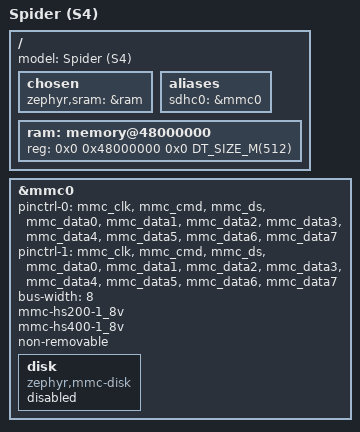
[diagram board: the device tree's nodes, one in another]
/*
 * Copyright (c) 2023 EPAM Systems
 *
 * SPDX-License-Identifier: Apache-2.0
 *
 */

/dts-v1/;
#include <mem.h>
#include <arm64/renesas/r8a779f.dtsi>
#include "spider-pinctrl.dtsi"

/ {
	model = "Spider (S4)";
	chosen {
		zephyr,sram = &ram;
	};

	/* These aliases are provided for compatibility with samples */
	aliases {
		sdhc0 = &mmc0;
	};

	ram: memory@48000000 {
		device_type = "mmio-sram";
		reg = <0x0 0x48000000 0x0 DT_SIZE_M(512)>;
	};
};

&mmc0 {
	pinctrl-0 = <&mmc_clk &mmc_cmd &mmc_ds
		&mmc_data0 &mmc_data1 &mmc_data2 &mmc_data3
		&mmc_data4 &mmc_data5 &mmc_data6 &mmc_data7>;
	pinctrl-1 = <&mmc_clk &mmc_cmd &mmc_ds
		&mmc_data0 &mmc_data1 &mmc_data2 &mmc_data3
		&mmc_data4 &mmc_data5 &mmc_data6 &mmc_data7>;
	pinctrl-names = "default", "uhs";
	disk {
		compatible = "zephyr,mmc-disk";
		status = "disabled";
	};
	bus-width = <8>;
	mmc-hs200-1_8v;
	mmc-hs400-1_8v;
	non-removable;
};
